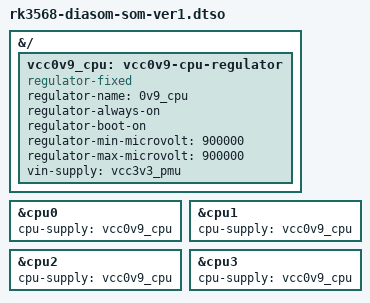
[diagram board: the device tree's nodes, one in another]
/* SPDX-License-Identifier: GPL-2.0+ */
/* SPDX-FileCopyrightText: Alexander Shiyan <shc_work@mail.ru> */

/dts-v1/;
/plugin/;

&{/} {
	vcc0v9_cpu: vcc0v9-cpu-regulator {
		compatible = "regulator-fixed";
		regulator-name = "0v9_cpu";
		regulator-always-on;
		regulator-boot-on;
		regulator-min-microvolt = <900000>;
		regulator-max-microvolt = <900000>;
		vin-supply = <&vcc3v3_pmu>;
	};
};

&cpu0 {
	cpu-supply = <&vcc0v9_cpu>;
};

&cpu1 {
	cpu-supply = <&vcc0v9_cpu>;
};

&cpu2 {
	cpu-supply = <&vcc0v9_cpu>;
};

&cpu3 {
	cpu-supply = <&vcc0v9_cpu>;
};
